CM_ "IMPORT _subaru_preglobal_2015.dbc"

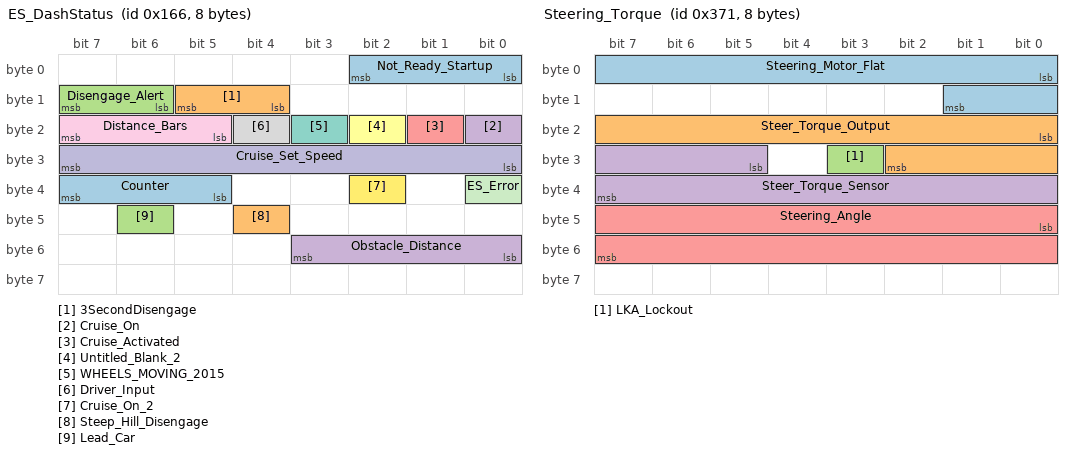
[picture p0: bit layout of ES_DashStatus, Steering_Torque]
BO_ 358 ES_DashStatus: 8 XXX
 SG_ Not_Ready_Startup : 0|3@1+ (1,0) [0|7] "" XXX
 SG_ 3SecondDisengage : 12|2@1+ (1,0) [0|3] "" XXX
 SG_ Disengage_Alert : 14|2@1+ (1,0) [0|3] "" XXX
 SG_ Cruise_On : 16|1@1+ (1,0) [0|7] "" XXX
 SG_ Cruise_Activated : 17|1@1+ (1,0) [0|3] "" XXX
 SG_ Untitled_Blank_2 : 18|1@1+ (1,0) [0|3] "" XXX
 SG_ WHEELS_MOVING_2015 : 19|1@1+ (1,0) [0|3] "" XXX
 SG_ Driver_Input : 20|1@1+ (1,0) [0|15] "" XXX
 SG_ Distance_Bars : 21|3@1+ (1,0) [0|3] "" XXX
 SG_ Cruise_Set_Speed : 24|8@1+ (1,0) [0|255] "" XXX
 SG_ ES_Error : 32|1@1+ (1,0) [0|3] "" XXX
 SG_ Cruise_On_2 : 34|1@1+ (1,0) [0|7] "" XXX
 SG_ Counter : 37|3@1+ (1,0) [0|7] "" XXX
 SG_ Steep_Hill_Disengage : 44|1@1+ (1,0) [0|3] "" XXX
 SG_ Lead_Car : 46|1@1+ (1,0) [0|255] "" XXX
 SG_ Obstacle_Distance : 48|4@1+ (5,0) [0|15] "m" XXX

BO_ 881 Steering_Torque: 8 XXX
 SG_ Steering_Motor_Flat : 0|10@1+ (32,0) [0|16500] "" XXX
 SG_ Steer_Torque_Output : 16|11@1- (-32,0) [-16500|16500] "" XXX
 SG_ LKA_Lockout : 27|1@1+ (1,0) [0|1] "" XXX
 SG_ Steer_Torque_Sensor : 29|11@1- (1,0) [-1500|1500] "" XXX
 SG_ Steering_Angle : 40|16@1- (-0.033,0) [-600|600] "" XXX

CM_ SG_ 320 Off_Throttle_2 "Less sensitive";
CM_ SG_ 320 Throttle_Body_ "Throttle related";
CM_ SG_ 328 Gear "15 = P, 14 = R, 0 = N, 1-6=gear";
CM_ SG_ 328 Gear_2 "15 = P, 14 = R, 0 = N, 1-6=gear";
CM_ SG_ 353 Button "1 = main, 2 = set shallow, 3 = set deep, 4 = resume shallow, 5 resume deep";
CM_ SG_ 354 RPM "20hz version of Transmission_Engine under Transmission";
CM_ SG_ 358 3SecondDisengage "seatbelt disengage";
CM_ SG_ 358 Disengage_Alert "seatbelt and steep hill disengage";
CM_ SG_ 358 ES_Error "No engagement until restart";
CM_ SG_ 358 Lead_Car "front car detected";
CM_ SG_ 359 Sig1Right_Depart "right depart, hill steep and seatbelt disengage";
CM_ SG_ 359 LKAS_Inactive_2017 "1 when not steering, 0 when lkas steering";
CM_ SG_ 359 Sig1Right_Depart_Front "object in front, right depart, hill steep and seatbelt disengage alert ";
CM_ SG_ 359 Left_Depart_Front "warning after acceleration into car in front and left depart";
CM_ SG_ 359 Sig1All_Depart "Left and right depart";
CM_ SG_ 359 Sig2All_Depart "Left and right depart";
CM_ SG_ 359 All_depart_2015 "always 1 on 2017";
CM_ SG_ 604 R_APPROACHING "Faster car approaching in far right lane";
CM_ SG_ 604 L_APPROACHING "Faster car approaching in far left lane";
CM_ SG_ 604 R_RCTA "Rear cross traffic alert, only when in R gear";
CM_ SG_ 604 L_RCTA "Rear cross traffic alert, only when in R gear";
CM_ SG_ 642 Counter "Affected by signals";
CM_ SG_ 642 RIGHT_BLINKER "0 off, 2 right, 1 left";
CM_ SG_ 642 SEATBELT_FL "Driver seatbelt";
CM_ SG_ 880 Steering_Voltage_Flat "receives later than 371";
VAL_ 328 Gear 0 "N" 1 "D" 2 "D" 3 "D" 4 "D" 5 "D" 6 "D" 14 "R" 15 "P";
VAL_ 1745 Units 0 "Metric" 1 "Imperial";
